# myChip register map
Vendor: ARM Ltd.; Series: ARMCM3; File version: 1.2
CPU: CM3 r2p1, little endian, no MPU, no FPU, 3 interrupt priority bits
Registers are 32-bit, read-write, reset 0x0 unless marked. A register's access mark holds for its fields unless they carry their own. Offsets are from the block's base; [hi:lo] are bit positions.

## TMR0
Base 0x40018000
Same registers: TMR1 0x40019000, TMR2 0x4001A000
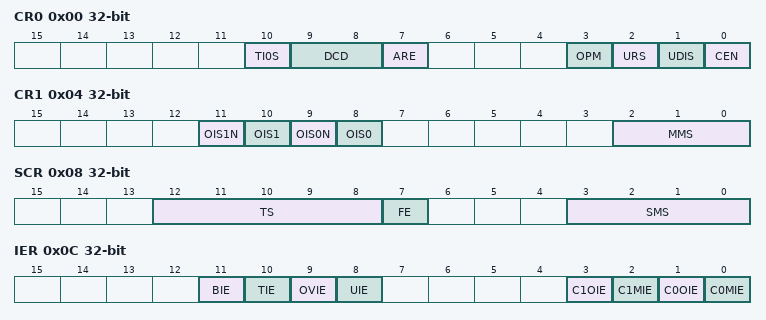
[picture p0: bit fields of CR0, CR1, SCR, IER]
0x00 CR0 — TMRx Control Register0
  [10] TI0S — TI0输入选择(TI0 Input Selection)
  [9:8] DCD — 时钟分频(Clock Division)
  [7] ARE — 自动重载使能(AutoReload Enable)
  [3] OPM — 单脉冲模式(One Pulse Mode)
  [2] URS — 更新事件源(Update Request Source)
  [1] UDIS — 更新禁止位(Update Disable)
  [0] CEN — 计数器使能位(Counter Enable)
0x04 CR1 — TMRx Control Register1
  [11] OIS1N — CH1N空闲状态输出电平(CH1N Output Idle-State)
  [10] OIS1 — CH1空闲状态输出电平(CH1 Output Idle-State)
  [9] OIS0N — CH0N空闲状态输出电平(CH0N Output Idle-State)
  [8] OIS0 — CH0空闲状态输出电平(CH0 Output Idle-State)
  [2:0] MMS — 主模式选择(Master Mode Selection)
0x08 SCR — TMRx Slave Control Register
  [12:8] TS — 触发选择(Trigger Selection)
  [7] FE — 主从快速同步使能(Master/Slave Fast-Sync Enable)
  [3:0] SMS — 从模式选择(Slave Mode Selection)
0x0C IER — TMRx Interrupt Enable Register
  [11] BIE — 断路中断使能(Break Interrupt Enable)
  [10] TIE — 触发中断使能(Trigger Interrupt Enable)
  [9] OVIE — 计数上溢中断使能(Overflow Interrupt Enable)
  [8] UIE — 更新中断使能(Update Interrupt Enable)
  [3] C1OIE — CH1重复捕获中断使能(CH1 OverCapture Interrupt Enable)
  [2] C1MIE — CH1比较中断使能(CH1 Capture/Compare Interrupt Enable)
  [1] C0OIE — CH0重复捕获中断使能(CH0 OverCapture Interrupt Enable)
  [0] C0MIE — CH0比较中断使能(CH0 Capture/Compare Interrupt Enable)
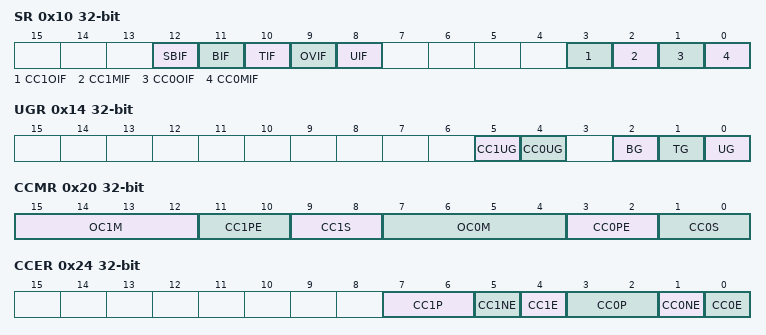
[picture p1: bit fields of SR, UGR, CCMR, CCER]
0x10 SR — TMRx Status Register
  [12] SBIF — 系统断路中断标志位(System Fault Break Interrupt Flag)
  [11] BIF — 断路中断标志位(Break Interrupt Flag)
  [10] TIF — 触发中断标志(Trigger Interrupt Flag)
  [9] OVIF — 计数器上溢中断标志位(Counter Overflow Interrupt Flag)
  [8] UIF — 更新中断标志(Update Interrupt Flag)
  [3] CC1OIF — CC1重复捕获成功中断标志位(CC1 OverCapture Interrupt Flag)
  [2] CC1MIF — CC1比较成功中断标志位(CC1 Capture/Compare Interrupt Flag)
  [1] CC0OIF — CC0重复捕获成功中断标志位(CC0 OverCapture Interrupt Flag)
  [0] CC0MIF — CC0比较成功中断标志位(CC0 Capture/Compare Interrupt Flag)
0x14 UGR — TMRx Update Generation Register
  [5] CC1UG — CC1捕获/比较更新事件生成(CC1 Capture/Compare Update Generation)
  [4] CC0UG — CC0捕获/比较更新事件生成(CC0 Capture/Compare Update Generation)
  [2] BG — 断路事件生成(Break Generation)
  [1] TG — 触发事件生成(Trigger Generation)
  [0] UG — 更新事件生成(Update Generation)
0x20 CCMR — TMRx Capture Compare Mode Register
  [15:12] OC1M — CC1输入滤波/输出比较模式选择(CC1 Input Filter/Output Compare Mode)
  [11:10] CC1PE — CC1输入捕获分频/比较自动加载使能(CC1 Compare Auto-Realod Enable)
  [9:8] CC1S — CC1捕获/比较方向选择(CC1 Capture Compare Selection)
  [7:4] OC0M — CC0输入滤波/输出比较模式选择(CC0 Input Filter/Output Compare Mode)
  [3:2] CC0PE — CC0输入捕获分频/比较自动加载使能(CC0 Compare Auto-Realod Enable)
  [1:0] CC0S — CC0捕获/比较方向选择(CC0 Capture Compare Selection)
0x24 CCER — TMRx Capture Compare Enable Register
  [7:6] CC1P — CC1捕获/比较极性选择(CC1 Compare/Capture Polarity)
  [5] CC1NE — CC1N捕获/比较互补通道使能(CC1N Capture/Compare Enable)
  [4] CC1E — CC1捕获/比较通道使能(CC1 Capture/Compare Enable)
  [3:2] CC0P — CC0捕获/比较极性选择(CC0 Compare/Capture Polarity)
  [1] CC0NE — CC0N捕获/比较互补通道使能(CC0N Capture/Compare Enable)
  [0] CC0E — CC0捕获/比较通道使能(CC0 Capture/Compare Enable)
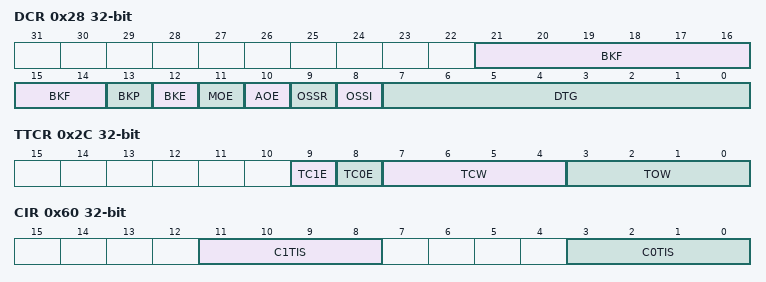
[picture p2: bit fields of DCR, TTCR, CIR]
0x28 DCR — TMRx Dead-Time Contorl Register
  [21:14] BKF — 断路滤波器(Break Filter)
  [13] BKP — 断路输入极性(Break Polarity)
  [12] BKE — 断路控制使能(Break Enable)
  [11] MOE — 主路输出使能(Main Output Enable)
  [10] AOE — 自动输出使能(Automatic Output Enable)
  [9] OSSR — 运行模式下关闭状态选择(Off-State Selection for Run-Mode)
  [8] OSSI — 空闲模式下关闭状态选择(Off-State Selection for Idle-Mode)
  [7:0] DTG — 配置死区时间选择(Dead-Time Generator Setup)
0x2C TTCR — TMRx Trigger Cycles Register
  [9] TC1E — TRGO CH1输出使能(Trigger CH1 Enable)
  [8] TC0E — TRGO CH0输出使能(Trigger CH0 Enable)
  [7:4] TCW — TRGCC脉冲宽度控制(Trigger Compare/Caputre Width)
  [3:0] TOW — TRGO脉冲宽度控制(Trigger Output Width)
0x30 CPR — TMRx Counter Period Register
  [15:0] CPV — 计数周期值(Counter Period Value)
0x38 PSCR — TMRx Prescaler Register
  [15:0] PSC — 预分频寄存器（Prescaler Value)
0x3C CNTR — TMRx Counter Register
  [15:0] CNT — 定时器计数值(Counter Value)
0x40 CRR — TMRx Counter Repeat Register
  [7:0] REP — 重复计数值(Counter Repeat Value)
0x50 CC0R — TMRx Capture Compare Register0
  [15:0] CC0V — CC0捕获/比较值(CC0 Capture/Compare Value)
0x54 CC1R — TMRx Capture Compare Register1
  [15:0] CC1V — CC1捕获/比较值(CC1 Capture/Compare Value)
0x60 CIR — TMRx Capture Input Register
  [11:8] C1TIS — CH1触发输入选择(CH1 Capture Input Selection)
  [3:0] C0TIS — CH0触发输入选择(CH0 Trigger Input Selection)
0x64 BPR — TMRx Break Polarity Register
  [15:0] BPOL — Break输入极性选择(Break Input Polarity Selection)
0x68 BER — TMRx Break Enable Register
  [15:0] BIEN — Break输入使能控制(Break Input Enable)
